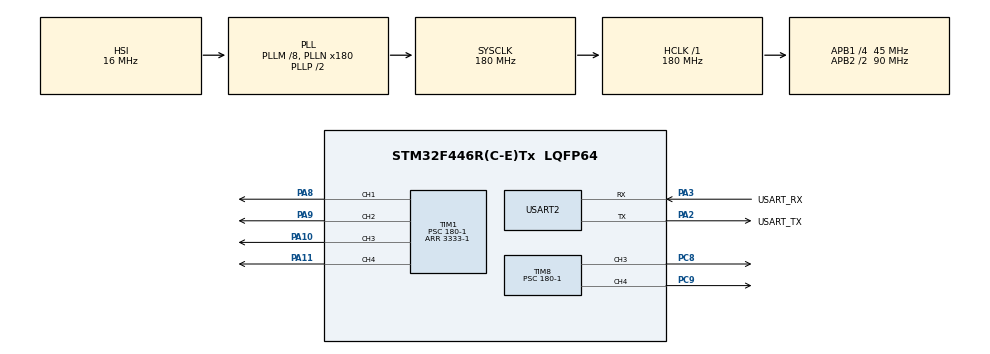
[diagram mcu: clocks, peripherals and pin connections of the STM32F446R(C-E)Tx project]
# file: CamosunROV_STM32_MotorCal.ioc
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IWDG.Prescaler=IWDG_PRESCALER_32
IWDG.Reload=500
Mcu.Family=STM32F4
Mcu.Name=STM32F446R(C-E)Tx
Mcu.Package=LQFP64
NVIC.PriorityGroup=NVIC_PRIORITYGROUP_0
PA10.Signal=S_TIM1_CH3
PA11.Signal=S_TIM1_CH4
PA13.GPIO_Label=TMS
PA13.Mode=Trace_Asynchronous_SW
PA13.Signal=SYS_JTMS-SWDIO
PA14.GPIO_Label=TCK
PA14.Mode=Trace_Asynchronous_SW
PA14.Signal=SYS_JTCK-SWCLK
PA2.GPIO_Label=USART_TX
PA2.Mode=Asynchronous
PA2.Signal=USART2_TX
PA3.GPIO_Label=USART_RX
PA3.Mode=Asynchronous
PA3.Signal=USART2_RX
PA8.Signal=S_TIM1_CH1
PA9.Signal=S_TIM1_CH2
PB3.GPIO_Label=SWO
PB3.Mode=Trace_Asynchronous_SW
PB3.Signal=SYS_JTDO-SWO
PC8.Signal=S_TIM8_CH3
PC9.Signal=S_TIM8_CH4
ProjectManager.HeapSize=0x200
ProjectManager.StackSize=0x400
ProjectManager.TargetToolchain=STM32CubeIDE
RCC.48MHZClocksFreq_Value=84000000
RCC.AHBFreq_Value=180000000
RCC.APB1CLKDivider=RCC_HCLK_DIV4
RCC.APB1Freq_Value=45000000
RCC.APB1TimFreq_Value=90000000
RCC.APB2CLKDivider=RCC_HCLK_DIV2
RCC.APB2Freq_Value=90000000
RCC.APB2TimFreq_Value=180000000
RCC.CortexFreq_Value=180000000
RCC.FLatency-AdvancedSettings=FLASH_LATENCY_5
RCC.HCLKFreq_Value=180000000
RCC.HSE_VALUE=8000000
RCC.HSI_VALUE=16000000
RCC.PLLM=8
RCC.PLLN=180
RCC.SYSCLKFreq_VALUE=180000000
RCC.SYSCLKSource=RCC_SYSCLKSOURCE_PLLCLK
RCC.USBFreq_Value=180000000
RCC.VCOOutputFreq_Value=360000000
SH.S_TIM1_CH1.0=TIM1_CH1,PWM Generation1 CH1
SH.S_TIM1_CH2.0=TIM1_CH2,PWM Generation2 CH2
SH.S_TIM1_CH3.0=TIM1_CH3,PWM Generation3 CH3
SH.S_TIM1_CH4.0=TIM1_CH4,PWM Generation4 CH4
SH.S_TIM8_CH3.0=TIM8_CH3,PWM Generation3 CH3
SH.S_TIM8_CH4.0=TIM8_CH4,PWM Generation4 CH4
TIM1.AutomaticOutput=TIM_AUTOMATICOUTPUT_DISABLE
TIM1.Channel-PWM\ Generation1\ CH1=TIM_CHANNEL_1
TIM1.Channel-PWM\ Generation2\ CH2=TIM_CHANNEL_2
TIM1.Channel-PWM\ Generation3\ CH3=TIM_CHANNEL_3
TIM1.Channel-PWM\ Generation4\ CH4=TIM_CHANNEL_4
TIM1.OCFastMode_PWM-PWM\ Generation1\ CH1=TIM_OCFAST_DISABLE
TIM1.OffStateIDLEMode=TIM_OSSI_ENABLE
TIM1.OffStateRunMode=TIM_OSSR_ENABLE
TIM1.Period=3333-1
TIM1.Prescaler=180-1
TIM8.Channel-PWM\ Generation3\ CH3=TIM_CHANNEL_3
TIM8.Channel-PWM\ Generation4\ CH4=TIM_CHANNEL_4
TIM8.OffStateIDLEMode=TIM_OSSI_ENABLE
TIM8.OffStateRunMode=TIM_OSSR_ENABLE
TIM8.Period=3333-1
TIM8.Prescaler=180-1
USART2.VirtualMode=VM_ASYNC
VP_IWDG_VS_IWDG.Mode=IWDG_Activate
VP_TIM1_VS_ClockSourceINT.Mode=Internal
VP_TIM8_VS_ClockSourceINT.Mode=Internal
board=NUCLEO-F446RE

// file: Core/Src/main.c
/* USER CODE BEGIN Header */
/**
 ******************************************************************************
 * @file           : main.c
 * @brief          : Main program body
 ******************************************************************************
 * @attention
 *
 * Copyright (c) 2026 STMicroelectronics.
 * All rights reserved.
 *
 * This software is licensed under terms that can be found in the LICENSE file
 * in the root directory of this software component.
 *
 ******************************************************************************
 */
/* USER CODE END Header */
#include "main.h"

/* USER CODE BEGIN Includes */
#include "motor_cal.h"

/* USER CODE END Includes */

IWDG_HandleTypeDef hiwdg;

TIM_HandleTypeDef htim1;
TIM_HandleTypeDef htim8;

UART_HandleTypeDef huart2;

void SystemClock_Config(void);
static void MX_GPIO_Init(void);
static void MX_USART2_UART_Init(void);
static void MX_TIM1_Init(void);
static void MX_TIM8_Init(void);
static void MX_IWDG_Init(void);

int main(void)
{

  /* MCU Configuration--------------------------------------------------------*/

  /* Reset of all peripherals, Initializes the Flash interface and the Systick. */
  HAL_Init();

  /* USER CODE BEGIN Init */
	__HAL_DBGMCU_FREEZE_IWDG(); // stop the watchdog while paused in the debugger
  /* USER CODE END Init */

  /* Configure the system clock */
  SystemClock_Config();

  /* Initialize all configured peripherals */
  MX_GPIO_Init();
  MX_USART2_UART_Init();
  MX_TIM1_Init();
  MX_TIM8_Init();
  /* USER CODE BEGIN 2 */
	// All six outputs to 1500 us (neutral), start the PWM, print the help text.
	motor_cal_init();

	// Watchdog: if the main loop ever hangs, the chip resets and the PWM pins
	// stop driving, so a thruster can't be left spinning. Started last so the
	// boot above can't trip it. MX_IWDG_Init() is set to "Do Not Generate
	// Function Call" in the .ioc, so CubeMX won't start it earlier.
	MX_IWDG_Init();
  /* USER CODE END 2 */

  /* Infinite loop */
	while (1) {

    /* USER CODE BEGIN 3 */
		HAL_IWDG_Refresh(&hiwdg);
		motor_cal_service(); // keyboard console on USART2, non-blocking
	}
  /* USER CODE END 3 */
}

void SystemClock_Config(void)
{
  RCC_OscInitTypeDef RCC_OscInitStruct = {0};
  RCC_ClkInitTypeDef RCC_ClkInitStruct = {0};

  /** Configure the main internal regulator output voltage
  */
  __HAL_RCC_PWR_CLK_ENABLE();
  __HAL_PWR_VOLTAGESCALING_CONFIG(PWR_REGULATOR_VOLTAGE_SCALE1);

  /** Initializes the RCC Oscillators according to the specified parameters
  * in the RCC_OscInitTypeDef structure.
  */
  RCC_OscInitStruct.OscillatorType = RCC_OSCILLATORTYPE_HSI|RCC_OSCILLATORTYPE_LSI;
  RCC_OscInitStruct.HSIState = RCC_HSI_ON;
  RCC_OscInitStruct.HSICalibrationValue = RCC_HSICALIBRATION_DEFAULT;
  RCC_OscInitStruct.LSIState = RCC_LSI_ON;
  RCC_OscInitStruct.PLL.PLLState = RCC_PLL_ON;
  RCC_OscInitStruct.PLL.PLLSource = RCC_PLLSOURCE_HSI;
  RCC_OscInitStruct.PLL.PLLM = 8;
  RCC_OscInitStruct.PLL.PLLN = 180;
  RCC_OscInitStruct.PLL.PLLP = RCC_PLLP_DIV2;
  RCC_OscInitStruct.PLL.PLLQ = 2;
  RCC_OscInitStruct.PLL.PLLR = 2;
  if (HAL_RCC_OscConfig(&RCC_OscInitStruct) != HAL_OK)
  {
    Error_Handler();
  }

  /** Activate the Over-Drive mode
  */
  if (HAL_PWREx_EnableOverDrive() != HAL_OK)
  {
    Error_Handler();
  }

  /** Initializes the CPU, AHB and APB buses clocks
  */
  RCC_ClkInitStruct.ClockType = RCC_CLOCKTYPE_HCLK|RCC_CLOCKTYPE_SYSCLK
                              |RCC_CLOCKTYPE_PCLK1|RCC_CLOCKTYPE_PCLK2;
  RCC_ClkInitStruct.SYSCLKSource = RCC_SYSCLKSOURCE_PLLCLK;
  RCC_ClkInitStruct.AHBCLKDivider = RCC_SYSCLK_DIV1;
  RCC_ClkInitStruct.APB1CLKDivider = RCC_HCLK_DIV4;
  RCC_ClkInitStruct.APB2CLKDivider = RCC_HCLK_DIV2;

  if (HAL_RCC_ClockConfig(&RCC_ClkInitStruct, FLASH_LATENCY_5) != HAL_OK)
  {
    Error_Handler();
  }
}

static void MX_IWDG_Init(void)
{

  hiwdg.Instance = IWDG;
  hiwdg.Init.Prescaler = IWDG_PRESCALER_32;
  hiwdg.Init.Reload = 500;
  if (HAL_IWDG_Init(&hiwdg) != HAL_OK)
  {
    Error_Handler();
  }

}

static void MX_TIM1_Init(void)
{

  TIM_ClockConfigTypeDef sClockSourceConfig = {0};
  TIM_MasterConfigTypeDef sMasterConfig = {0};
  TIM_OC_InitTypeDef sConfigOC = {0};
  TIM_BreakDeadTimeConfigTypeDef sBreakDeadTimeConfig = {0};

  htim1.Instance = TIM1;
  htim1.Init.Prescaler = 180-1;
  htim1.Init.CounterMode = TIM_COUNTERMODE_UP;
  htim1.Init.Period = 3333-1;
  htim1.Init.ClockDivision = TIM_CLOCKDIVISION_DIV1;
  htim1.Init.RepetitionCounter = 0;
  htim1.Init.AutoReloadPreload = TIM_AUTORELOAD_PRELOAD_DISABLE;
  if (HAL_TIM_Base_Init(&htim1) != HAL_OK)
  {
    Error_Handler();
  }
  sClockSourceConfig.ClockSource = TIM_CLOCKSOURCE_INTERNAL;
  if (HAL_TIM_ConfigClockSource(&htim1, &sClockSourceConfig) != HAL_OK)
  {
    Error_Handler();
  }
  if (HAL_TIM_PWM_Init(&htim1) != HAL_OK)
  {
    Error_Handler();
  }
  sMasterConfig.MasterOutputTrigger = TIM_TRGO_RESET;
  sMasterConfig.MasterSlaveMode = TIM_MASTERSLAVEMODE_DISABLE;
  if (HAL_TIMEx_MasterConfigSynchronization(&htim1, &sMasterConfig) != HAL_OK)
  {
    Error_Handler();
  }
  sConfigOC.OCMode = TIM_OCMODE_PWM1;
  sConfigOC.Pulse = 0;
  sConfigOC.OCPolarity = TIM_OCPOLARITY_HIGH;
  sConfigOC.OCNPolarity = TIM_OCNPOLARITY_HIGH;
  sConfigOC.OCFastMode = TIM_OCFAST_DISABLE;
  sConfigOC.OCIdleState = TIM_OCIDLESTATE_RESET;
  sConfigOC.OCNIdleState = TIM_OCNIDLESTATE_RESET;
  if (HAL_TIM_PWM_ConfigChannel(&htim1, &sConfigOC, TIM_CHANNEL_1) != HAL_OK)
  {
    Error_Handler();
  }
  if (HAL_TIM_PWM_ConfigChannel(&htim1, &sConfigOC, TIM_CHANNEL_2) != HAL_OK)
  {
    Error_Handler();
  }
  if (HAL_TIM_PWM_ConfigChannel(&htim1, &sConfigOC, TIM_CHANNEL_3) != HAL_OK)
  {
    Error_Handler();
  }
  if (HAL_TIM_PWM_ConfigChannel(&htim1, &sConfigOC, TIM_CHANNEL_4) != HAL_OK)
  {
    Error_Handler();
  }
  sBreakDeadTimeConfig.OffStateRunMode = TIM_OSSR_ENABLE;
  sBreakDeadTimeConfig.OffStateIDLEMode = TIM_OSSI_ENABLE;
  sBreakDeadTimeConfig.LockLevel = TIM_LOCKLEVEL_OFF;
  sBreakDeadTimeConfig.DeadTime = 0;
  sBreakDeadTimeConfig.BreakState = TIM_BREAK_DISABLE;
  sBreakDeadTimeConfig.BreakPolarity = TIM_BREAKPOLARITY_HIGH;
  sBreakDeadTimeConfig.AutomaticOutput = TIM_AUTOMATICOUTPUT_DISABLE;
  if (HAL_TIMEx_ConfigBreakDeadTime(&htim1, &sBreakDeadTimeConfig) != HAL_OK)
  {
    Error_Handler();
  }
  HAL_TIM_MspPostInit(&htim1);

}

static void MX_TIM8_Init(void)
{

  TIM_ClockConfigTypeDef sClockSourceConfig = {0};
  TIM_MasterConfigTypeDef sMasterConfig = {0};
  TIM_OC_InitTypeDef sConfigOC = {0};
  TIM_BreakDeadTimeConfigTypeDef sBreakDeadTimeConfig = {0};

  htim8.Instance = TIM8;
  htim8.Init.Prescaler = 180-1;
  htim8.Init.CounterMode = TIM_COUNTERMODE_UP;
  htim8.Init.Period = 3333-1;
  htim8.Init.ClockDivision = TIM_CLOCKDIVISION_DIV1;
  htim8.Init.RepetitionCounter = 0;
  htim8.Init.AutoReloadPreload = TIM_AUTORELOAD_PRELOAD_DISABLE;
  if (HAL_TIM_Base_Init(&htim8) != HAL_OK)
  {
    Error_Handler();
  }
  sClockSourceConfig.ClockSource = TIM_CLOCKSOURCE_INTERNAL;
  if (HAL_TIM_ConfigClockSource(&htim8, &sClockSourceConfig) != HAL_OK)
  {
    Error_Handler();
  }
  if (HAL_TIM_PWM_Init(&htim8) != HAL_OK)
  {
    Error_Handler();
  }
  sMasterConfig.MasterOutputTrigger = TIM_TRGO_RESET;
  sMasterConfig.MasterSlaveMode = TIM_MASTERSLAVEMODE_DISABLE;
  if (HAL_TIMEx_MasterConfigSynchronization(&htim8, &sMasterConfig) != HAL_OK)
  {
    Error_Handler();
  }
  sConfigOC.OCMode = TIM_OCMODE_PWM1;
  sConfigOC.Pulse = 0;
  sConfigOC.OCPolarity = TIM_OCPOLARITY_HIGH;
  sConfigOC.OCNPolarity = TIM_OCNPOLARITY_HIGH;
  sConfigOC.OCFastMode = TIM_OCFAST_DISABLE;
  sConfigOC.OCIdleState = TIM_OCIDLESTATE_RESET;
  sConfigOC.OCNIdleState = TIM_OCNIDLESTATE_RESET;
  if (HAL_TIM_PWM_ConfigChannel(&htim8, &sConfigOC, TIM_CHANNEL_3) != HAL_OK)
  {
    Error_Handler();
  }
  if (HAL_TIM_PWM_ConfigChannel(&htim8, &sConfigOC, TIM_CHANNEL_4) != HAL_OK)
  {
    Error_Handler();
  }
  sBreakDeadTimeConfig.OffStateRunMode = TIM_OSSR_ENABLE;
  sBreakDeadTimeConfig.OffStateIDLEMode = TIM_OSSI_ENABLE;
  sBreakDeadTimeConfig.LockLevel = TIM_LOCKLEVEL_OFF;
  sBreakDeadTimeConfig.DeadTime = 0;
  sBreakDeadTimeConfig.BreakState = TIM_BREAK_DISABLE;
  sBreakDeadTimeConfig.BreakPolarity = TIM_BREAKPOLARITY_HIGH;
  sBreakDeadTimeConfig.AutomaticOutput = TIM_AUTOMATICOUTPUT_DISABLE;
  if (HAL_TIMEx_ConfigBreakDeadTime(&htim8, &sBreakDeadTimeConfig) != HAL_OK)
  {
    Error_Handler();
  }
  HAL_TIM_MspPostInit(&htim8);

}

static void MX_USART2_UART_Init(void)
{

  huart2.Instance = USART2;
  huart2.Init.BaudRate = 115200;
  huart2.Init.WordLength = UART_WORDLENGTH_8B;
  huart2.Init.StopBits = UART_STOPBITS_1;
  huart2.Init.Parity = UART_PARITY_NONE;
  huart2.Init.Mode = UART_MODE_TX_RX;
  huart2.Init.HwFlowCtl = UART_HWCONTROL_NONE;
  huart2.Init.OverSampling = UART_OVERSAMPLING_16;
  if (HAL_UART_Init(&huart2) != HAL_OK)
  {
    Error_Handler();
  }

}

static void MX_GPIO_Init(void)
{

  /* GPIO Ports Clock Enable */
  __HAL_RCC_GPIOC_CLK_ENABLE();
  __HAL_RCC_GPIOA_CLK_ENABLE();
  __HAL_RCC_GPIOB_CLK_ENABLE();

}

void Error_Handler(void)
{
	__disable_irq();
	while (1) {
	}
}
